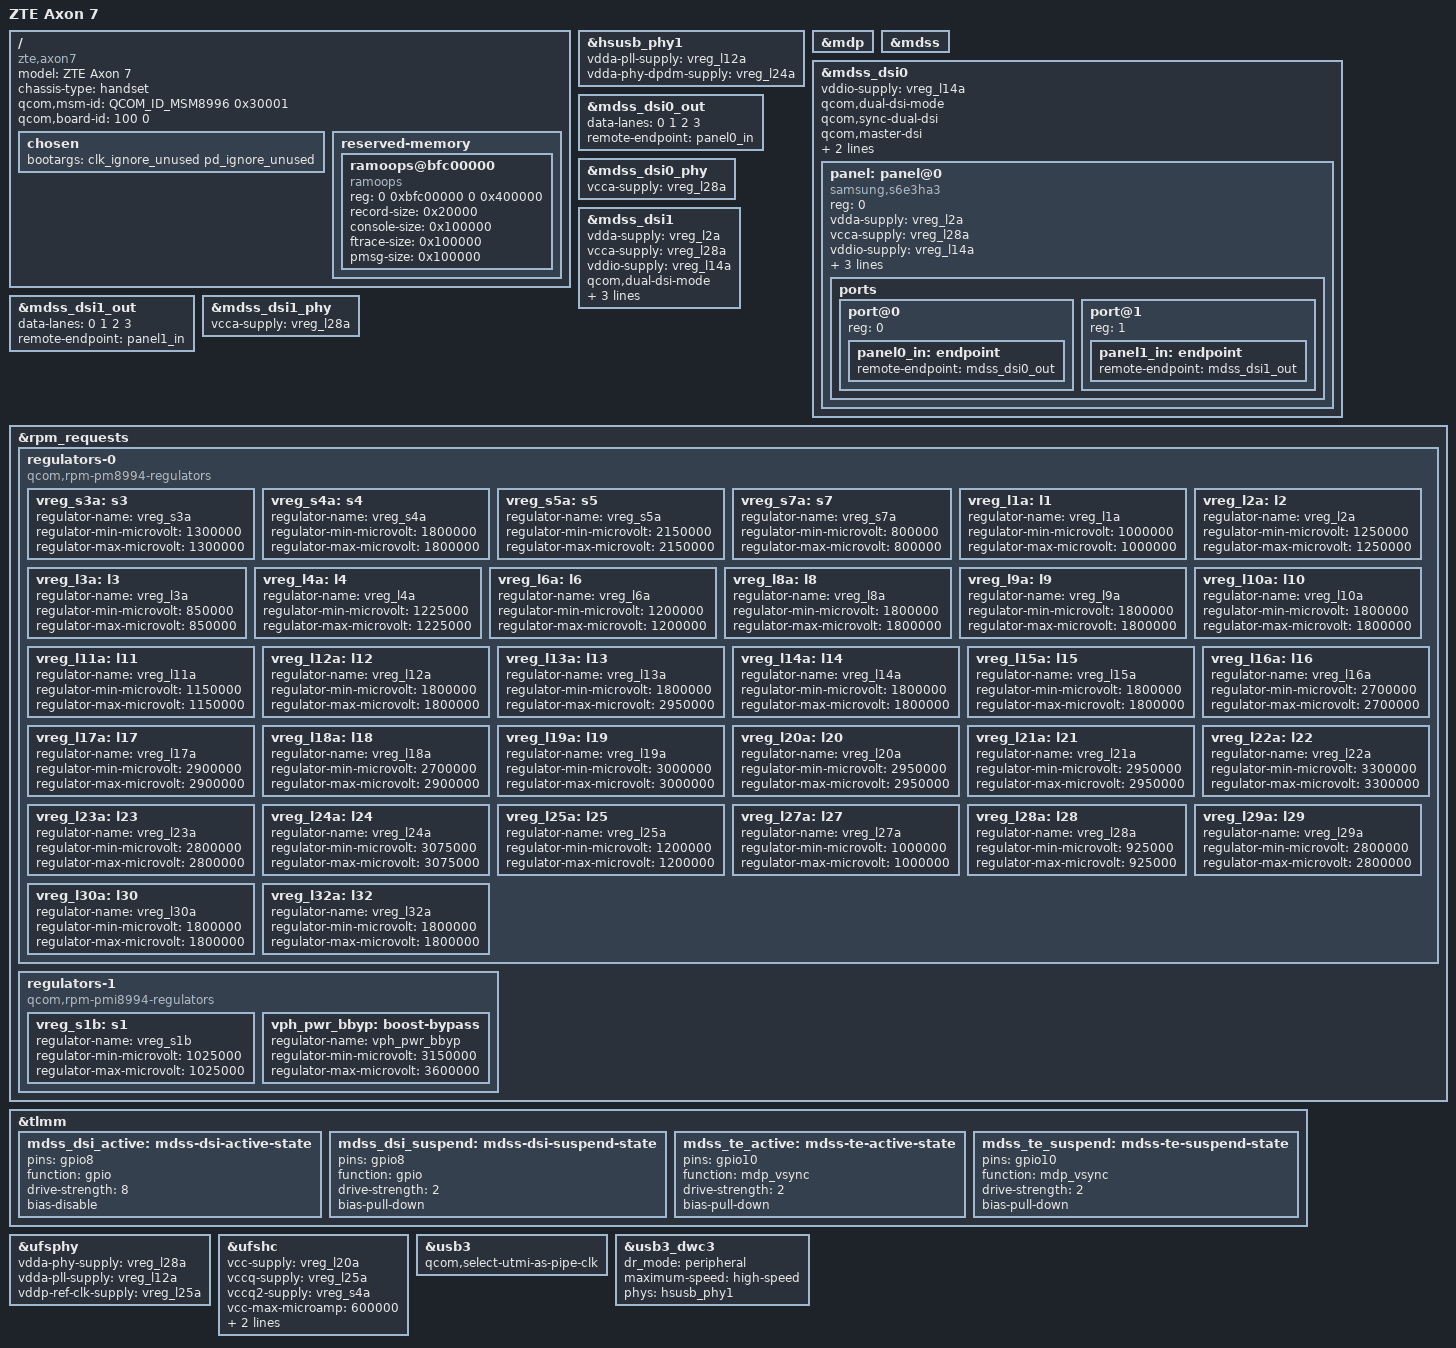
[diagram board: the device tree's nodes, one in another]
// SPDX-License-Identifier: GPL-2.0
/*
 * Copyright (c) 2023, David Wronek <davidwronek@gmail.com>
 */

/dts-v1/;

#include <dt-bindings/arm/qcom,ids.h>
#include "msm8996.dtsi"
#include "pm8994.dtsi"
#include "pmi8994.dtsi"
#include "pmi8996.dtsi"

/ {
	model = "ZTE Axon 7";
	compatible = "zte,axon7", "qcom,msm8996";
	chassis-type = "handset";
	qcom,msm-id = <QCOM_ID_MSM8996 0x30001>;
	qcom,board-id = <100 0>;

	chosen {
		bootargs = "clk_ignore_unused pd_ignore_unused";
	};

	reserved-memory {
		#address-cells = <2>;
		#size-cells = <2>;
		ranges;

		ramoops@bfc00000 {
			compatible = "ramoops";
			reg = <0 0xbfc00000 0 0x400000>;
			record-size = <0x20000>;
			console-size = <0x100000>;
			ftrace-size = <0x100000>;
			pmsg-size = <0x100000>;
		};
	};
};

&hsusb_phy1 {
	status = "okay";

	vdda-pll-supply = <&vreg_l12a>;
	vdda-phy-dpdm-supply = <&vreg_l24a>;
};

&mdp {
    status = "okay";
};

&mdss {
    status = "okay";
};

&mdss_dsi0 {
	vddio-supply = <&vreg_l14a>;
	qcom,dual-dsi-mode;
	qcom,sync-dual-dsi;
	qcom,master-dsi;
	status = "okay";

	vdda-supply = <&vreg_l2a>;
	vcca-supply = <&vreg_l28a>;
	vddio-supply = <&vreg_l14a>;

	panel: panel@0 {
		compatible = "samsung,s6e3ha3";
		reg = <0>;

		vdda-supply = <&vreg_l2a>;
		vcca-supply = <&vreg_l28a>;
		vddio-supply = <&vreg_l14a>;

		reset-gpios = <&tlmm 8 GPIO_ACTIVE_LOW>;

		pinctrl-names = "default", "sleep";
		pinctrl-0 = <&mdss_dsi_active &mdss_te_active>;
		pinctrl-1 = <&mdss_dsi_suspend &mdss_te_suspend>;

		ports {
			#address-cells = <1>;
			#size-cells = <0>;

			port@0 {
				reg = <0>;
				panel0_in: endpoint {
					remote-endpoint = <&mdss_dsi0_out>;
				};
			};

			port@1 {
				reg = <1>;
				panel1_in: endpoint {
					remote-endpoint = <&mdss_dsi1_out>;
				};
			};
		};
	};
};

&mdss_dsi0_out {
	data-lanes = <0 1 2 3>;
	remote-endpoint = <&panel0_in>;
};

&mdss_dsi0_phy {
	vcca-supply = <&vreg_l28a>;
	status = "okay";
};

&mdss_dsi1 {
	vdda-supply = <&vreg_l2a>;
	vcca-supply = <&vreg_l28a>;
	vddio-supply = <&vreg_l14a>;
	qcom,dual-dsi-mode;
	qcom,sync-dual-dsi;
	/* DSI1 is slave, so use DSI0 clocks */
	assigned-clock-parents = <&mdss_dsi0_phy 0>, <&mdss_dsi0_phy 1>;
	status = "okay";
};

&mdss_dsi1_out {
	data-lanes = <0 1 2 3>;
	remote-endpoint = <&panel1_in>;
};

&mdss_dsi1_phy {
	vcca-supply = <&vreg_l28a>;
	status = "okay";
};

&rpm_requests {
	regulators-0 {
		compatible = "qcom,rpm-pm8994-regulators";

		vreg_s3a: s3 {
			regulator-name = "vreg_s3a";
			regulator-min-microvolt = <1300000>;
			regulator-max-microvolt = <1300000>;
		};

		vreg_s4a: s4 {
			regulator-name = "vreg_s4a";
			regulator-min-microvolt = <1800000>;
			regulator-max-microvolt = <1800000>;
		};

		vreg_s5a: s5 {
			regulator-name = "vreg_s5a";
			regulator-min-microvolt = <2150000>;
			regulator-max-microvolt = <2150000>;
		};

		vreg_s7a: s7 {
			regulator-name = "vreg_s7a";
			regulator-min-microvolt = <800000>;
			regulator-max-microvolt = <800000>;
		};

		vreg_l1a: l1 {
			regulator-name = "vreg_l1a";
			regulator-min-microvolt = <1000000>;
			regulator-max-microvolt = <1000000>;
		};

		vreg_l2a: l2 {
			regulator-name = "vreg_l2a";
			regulator-min-microvolt = <1250000>;
			regulator-max-microvolt = <1250000>;
		};

		vreg_l3a: l3 {
			regulator-name = "vreg_l3a";
			regulator-min-microvolt = <850000>;
			regulator-max-microvolt = <850000>;
		};

		vreg_l4a: l4 {
			regulator-name = "vreg_l4a";
			regulator-min-microvolt = <1225000>;
			regulator-max-microvolt = <1225000>;
		};

		vreg_l6a: l6 {
			regulator-name = "vreg_l6a";
			regulator-min-microvolt = <1200000>;
			regulator-max-microvolt = <1200000>;
		};

		vreg_l8a: l8 {
			regulator-name = "vreg_l8a";
			regulator-min-microvolt = <1800000>;
			regulator-max-microvolt = <1800000>;
		};

		vreg_l9a: l9 {
			regulator-name = "vreg_l9a";
			regulator-min-microvolt = <1800000>;
			regulator-max-microvolt = <1800000>;
		};

		vreg_l10a: l10 {
			regulator-name = "vreg_l10a";
			regulator-min-microvolt = <1800000>;
			regulator-max-microvolt = <1800000>;
		};

		vreg_l11a: l11 {
			regulator-name = "vreg_l11a";
			regulator-min-microvolt = <1150000>;
			regulator-max-microvolt = <1150000>;
		};

		vreg_l12a: l12 {
			regulator-name = "vreg_l12a";
			regulator-min-microvolt = <1800000>;
			regulator-max-microvolt = <1800000>;
		};

		vreg_l13a: l13 {
			regulator-name = "vreg_l13a";
			regulator-min-microvolt = <1800000>;
			regulator-max-microvolt = <2950000>;
		};

		vreg_l14a: l14 {
			regulator-name = "vreg_l14a";
			regulator-min-microvolt = <1800000>;
			regulator-max-microvolt = <1800000>;
		};

		vreg_l15a: l15 {
			regulator-name = "vreg_l15a";
			regulator-min-microvolt = <1800000>;
			regulator-max-microvolt = <1800000>;
		};

		vreg_l16a: l16 {
			regulator-name = "vreg_l16a";
			regulator-min-microvolt = <2700000>;
			regulator-max-microvolt = <2700000>;
		};

		vreg_l17a: l17 {
			regulator-name = "vreg_l17a";
			regulator-min-microvolt = <2900000>;
			regulator-max-microvolt = <2900000>;
		};

		vreg_l18a: l18 {
			regulator-name = "vreg_l18a";
			regulator-min-microvolt = <2700000>;
			regulator-max-microvolt = <2900000>;
		};

		vreg_l19a: l19 {
			regulator-name = "vreg_l19a";
			regulator-min-microvolt = <3000000>;
			regulator-max-microvolt = <3000000>;
		};

		vreg_l20a: l20 {
			regulator-name = "vreg_l20a";
			regulator-min-microvolt = <2950000>;
			regulator-max-microvolt = <2950000>;
		};

		vreg_l21a: l21 {
			regulator-name = "vreg_l21a";
			regulator-min-microvolt = <2950000>;
			regulator-max-microvolt = <2950000>;
		};

		vreg_l22a: l22 {
			regulator-name = "vreg_l22a";
			regulator-min-microvolt = <3300000>;
			regulator-max-microvolt = <3300000>;
		};

		vreg_l23a: l23 {
			regulator-name = "vreg_l23a";
			regulator-min-microvolt = <2800000>;
			regulator-max-microvolt = <2800000>;
		};

		vreg_l24a: l24 {
			regulator-name = "vreg_l24a";
			regulator-min-microvolt = <3075000>;
			regulator-max-microvolt = <3075000>;
		};

		vreg_l25a: l25 {
			regulator-name = "vreg_l25a";
			regulator-min-microvolt = <1200000>;
			regulator-max-microvolt = <1200000>;
		};

		vreg_l27a: l27 {
			regulator-name = "vreg_l27a";
			regulator-min-microvolt = <1000000>;
			regulator-max-microvolt = <1000000>;
		};

		vreg_l28a: l28 {
			regulator-name = "vreg_l28a";
			regulator-min-microvolt = <925000>;
			regulator-max-microvolt = <925000>;
		};

		vreg_l29a: l29 {
			regulator-name = "vreg_l29a";
			regulator-min-microvolt = <2800000>;
			regulator-max-microvolt = <2800000>;
		};

		vreg_l30a: l30 {
			regulator-name = "vreg_l30a";
			regulator-min-microvolt = <1800000>;
			regulator-max-microvolt = <1800000>;
		};

		vreg_l32a: l32 {
			regulator-name = "vreg_l32a";
			regulator-min-microvolt = <1800000>;
			regulator-max-microvolt = <1800000>;
		};
	};

	regulators-1 {
		compatible = "qcom,rpm-pmi8994-regulators";

		vreg_s1b: s1 {
			regulator-name = "vreg_s1b";
			regulator-min-microvolt = <1025000>;
			regulator-max-microvolt = <1025000>;
		};

		vph_pwr_bbyp: boost-bypass {
			regulator-name = "vph_pwr_bbyp";
			regulator-min-microvolt = <3150000>;
			regulator-max-microvolt = <3600000>;
		};
	};
};

&tlmm {
	mdss_dsi_active: mdss-dsi-active-state {
		pins = "gpio8";
		function = "gpio";
		drive-strength = <8>;
		bias-disable;
	};

	mdss_dsi_suspend: mdss-dsi-suspend-state {
		pins = "gpio8";
		function = "gpio";
		drive-strength = <2>;
		bias-pull-down;
	};

	mdss_te_active: mdss-te-active-state {
		pins = "gpio10";
		function = "mdp_vsync";
		drive-strength = <2>;
		bias-pull-down;
	};

	mdss_te_suspend: mdss-te-suspend-state {
		pins = "gpio10";
		function = "mdp_vsync";
		drive-strength = <2>;
		bias-pull-down;
	};
};

&ufsphy {
	vdda-phy-supply = <&vreg_l28a>;
	vdda-pll-supply = <&vreg_l12a>;
	vddp-ref-clk-supply = <&vreg_l25a>;
	status = "okay";
};

&ufshc {
	vcc-supply = <&vreg_l20a>;
	vccq-supply = <&vreg_l25a>;
	vccq2-supply = <&vreg_s4a>;
	vcc-max-microamp = <600000>;
	vccq-max-microamp = <450000>;
	vccq2-max-microamp = <450000>;
	status = "okay";
};

&usb3 {
	qcom,select-utmi-as-pipe-clk;
	status = "okay";
};

&usb3_dwc3 {
	dr_mode = "peripheral";
	maximum-speed = "high-speed";
	phys = <&hsusb_phy1>;
	phy-names = "usb2-phy";
};
